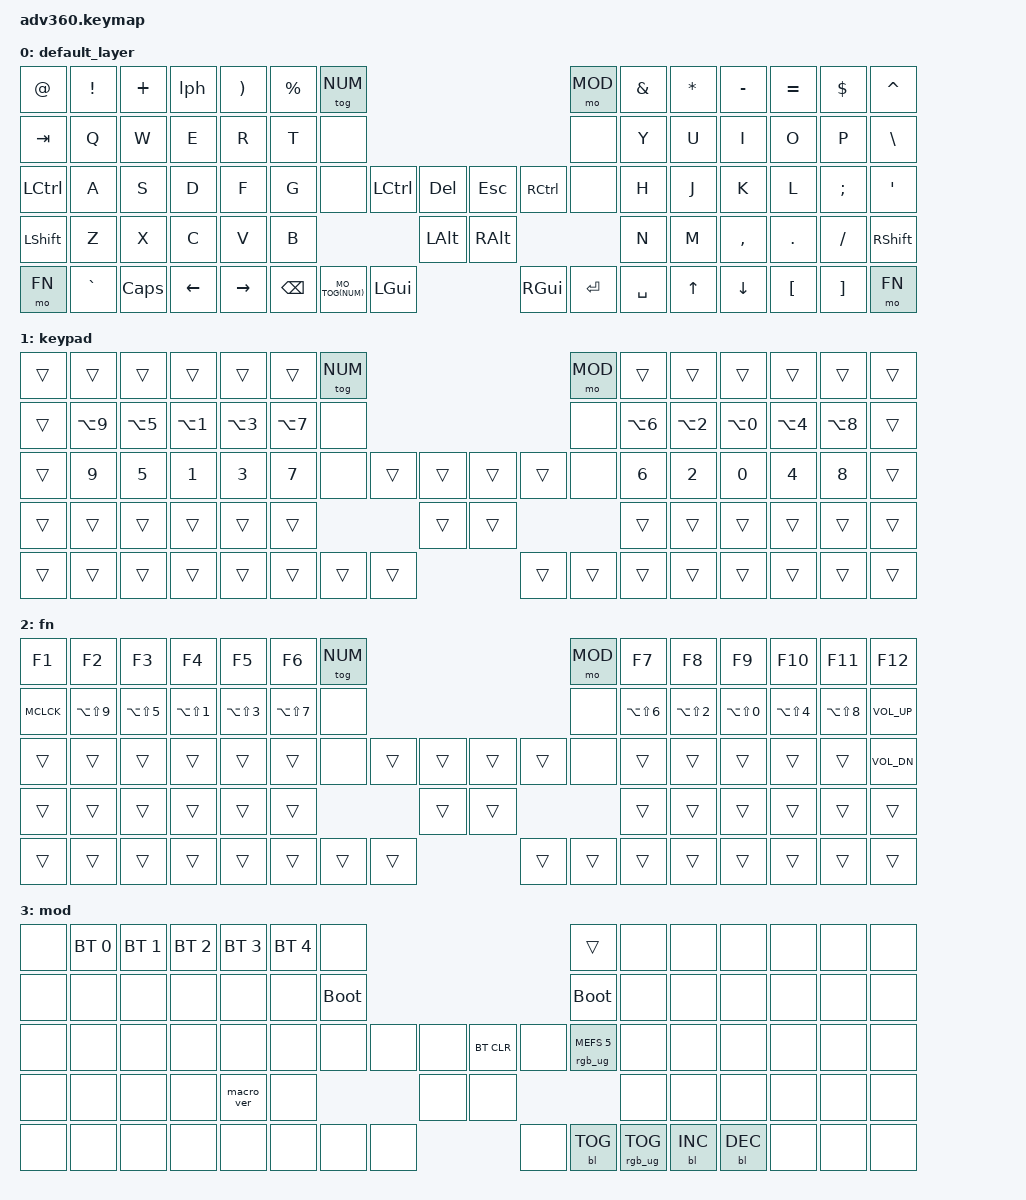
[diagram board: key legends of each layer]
#include <behaviors.dtsi>
#include <dt-bindings/zmk/keys.h>
#include <dt-bindings/zmk/bt.h>
#include <dt-bindings/zmk/rgb.h>
#include <dt-bindings/zmk/backlight.h>

#define DEF 0
#define NUM 1
#define FN 2
#define MOD 3

#define TMX    LC(A)
#define I3   LALT


// Mac specific
#define MCLCK   LG(LC(Q))

#define MO_TOG(layer) &mo_tog layer layer   // Macro to apply momentary-layer-on-hold/toggle-layer-on-tap to a specific layer

&lt {
    quick_tap_ms = <200>;
};

/ {
    behaviors {
      #include "macros.dtsi"
      #include "version.dtsi"
      #ifndef VERSION_MACRO
      macro_ver: macro_ver {
        compatible = "zmk,behavior-macro";
        label = "macro_version";
        #binding-cells = <0>;
        bindings = <&kp RET>;
      };
      #endif

      hm: homerow_mods {
          compatible = "zmk,behavior-hold-tap";
          label = "HOMEROW_MODS";
          #binding-cells = <2>;
          tapping-term-ms = <200>;
          quick_tap_ms = <175>;
          flavor = "tap-preferred";
          bindings = <&kp>, <&kp>;
      };

      mo_tog: behavior_mo_tog {
          compatible = "zmk,behavior-hold-tap";
          #binding-cells = <2>;
          flavor = "hold-preferred";
          tapping-term-ms = <200>;
          bindings = <&mo>, <&tog>;
      };

      lph: lph {
          compatible = "zmk,behavior-mod-morph";
          label = "lph";
          #binding-cells = <0>;
          bindings = <&kp LPAR>, <&kp HASH>;
          mods = <(MOD_LGUI|MOD_LSFT|MOD_RGUI|MOD_RSFT)>;
      };
    };

  keymap {
    compatible = "zmk,keymap";
    
    // TODO: add these to some layers: HOME, END, PG_UP, PG_DN
    // commentary:
    // 1. swap plus and equal. make it left-to-right motion. plus on left, equal on right.
    // 2. make top row of KP trans, because during number mode, I want to access the symbols
    // 3. LA(LS(N1)) should be moved to FN layer
    // 4. LA(N1) should be top - 1 row on KP layer, basically replacing LA(LS(N1))


    default_layer {
      bindings = <
        &kp AT    &kp EXCL  &kp PLUS  &lph     &kp RPAR   &kp PRCNT &tog NUM                                                           &mo MOD &kp AMPS &kp STAR &kp MINUS &kp EQUAL &kp DLLR &kp CARET
        &kp TAB   &kp Q     &kp W     &kp E    &kp R      &kp T     &none                                                              &none   &kp Y    &kp U    &kp I     &kp O    &kp P    &kp BSLH
        &kp LCTRL &kp A     &kp S     &kp D    &kp F      &kp G     &none           &kp LCTRL   &kp DEL  &kp ESC   &kp RCTRL           &none   &kp H    &kp J    &kp K     &kp L    &kp SEMI &kp SQT
        &kp LSHFT &kp Z     &kp X     &kp C    &kp V      &kp B                                 &kp LALT &kp RALT                              &kp N    &kp M    &kp COMMA &kp DOT  &kp FSLH &kp RSHFT
        &mo FN    &kp GRAVE &kp CAPS  &kp LEFT &kp RIGHT                   &kp BSPC MO_TOG(NUM) &kp LGUI &kp RGUI &kp ENTER &kp SPACE                   &kp UP   &kp DOWN  &kp LBKT &kp RBKT &mo FN
      >;
    };
    keypad {
      bindings = <

        &trans   &trans     &trans     &trans      &trans     &trans     &tog NUM                                          &mo MOD   &trans     &trans     &trans     &trans     &trans     &trans
        &trans   &kp LA(N9) &kp LA(N5) &kp LA(N1)  &kp LA(N3) &kp LA(N7) &none                                             &none     &kp LA(N6) &kp LA(N2) &kp LA(N0) &kp LA(N4) &kp LA(N8) &trans
        &trans   &kp N9     &kp N5     &kp N1      &kp N3     &kp N7     &none        &trans &trans &trans &trans          &none     &kp N6     &kp N2     &kp N0     &kp N4     &kp N8     &trans
        &trans   &trans     &trans     &trans      &trans     &trans                     &trans &trans                               &trans     &trans     &trans     &trans     &trans     &trans
        &trans   &trans     &trans     &trans      &trans                      &trans &trans &trans &trans &trans &trans                        &trans     &trans     &trans     &trans     &trans
      >;
    };
    fn {
      bindings = <
        &kp F1 &kp F2    &kp F3 &kp F4 &kp F5 &kp F6 &tog NUM                                         &mo MOD &kp F7 &kp F8 &kp F9 &kp F10 &kp F11 &kp F12
        &kp MCLCK &kp LA(LS(N9)) &kp LA(LS(N5)) &kp LA(LS(N1))  &kp LA(LS(N3)) &kp LA(LS(N7))  &none  &none   &kp LA(LS(N6)) &kp LA(LS(N2)) &kp LA(LS(N0)) &kp LA(LS(N4)) &kp LA(LS(N8))  &kp C_VOL_UP
        &trans &trans    &trans &trans &trans &trans  &none        &trans &trans &trans &trans        &none   &trans &trans &trans &trans  &trans  &kp C_VOL_DN
        &trans &trans    &trans &trans &trans &trans                      &trans &trans                       &trans &trans &trans &trans  &trans  &trans
        &trans &trans    &trans &trans &trans               &trans &trans &trans &trans &trans &trans                &trans &trans &trans  &trans  &trans
      >;
    };
    mod {
      bindings = <
        &none &bt BT_SEL 0 &bt BT_SEL 1 &bt BT_SEL 2 &bt BT_SEL 3 &bt BT_SEL 4 &none                                                                     &trans                 &none        &none        &none        &none &none &none
        &none &none        &none        &none        &none        &none        &bootloader                                                               &bootloader            &none        &none        &none        &none &none &none
        &none &none        &none        &none        &none        &none        &none                   &none &none &bt BT_CLR &none                      &rgb_ug RGB_MEFS_CMD 5 &none        &none        &none        &none &none &none
        &none &none        &none        &none        &macro_ver   &none                                      &none &none                                                        &none        &none        &none        &none &none &none
        &none &none        &none        &none        &none                                       &none &none &none &none      &bl BL_TOG &rgb_ug RGB_TOG                                     &bl BL_INC   &bl BL_DEC   &none &none &none
      >;
    };
  };
};
